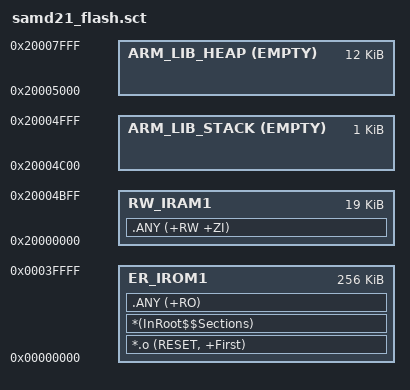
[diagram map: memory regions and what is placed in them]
;*****************************************************************
;* SAMD21 linker scatter file (running code from internal FLASH) *
;*****************************************************************

LR_IROM1 0x00000000 0x40000
{
   ER_IROM1 0x00000000 0x40000
   {
      *.o (RESET, +First)
      *(InRoot$$Sections)
      .ANY (+RO)
   }
   
   RW_IRAM1 0x20000000 0x4C00
   { 
      .ANY (+RW +ZI)
   }
   
   ARM_LIB_STACK 0x20005000 EMPTY -0x400
   {
   }
   
   ARM_LIB_HEAP 0x20005000 EMPTY 0x3000
   {
   }
}
